# STM32H563_USB_PMA register map
File version: 1.6
STM32G563xx
Registers are 32-bit, read-write, reset 0x0 unless marked. A register's access mark holds for its fields unless they carry their own. Offsets are from the block's base; lines under a group give offsets from that group; [hi:lo] are bit positions; {n}, {i} and the like mark numbered series; 'fields as' and 'values as' point back to an identical list; <NAME> marks a mode.

## Memory map
0x40016400 USB_PMA size 0x400 — USB_PMA2

## USB_PMA — USB_PMA2
Base 0x40016400
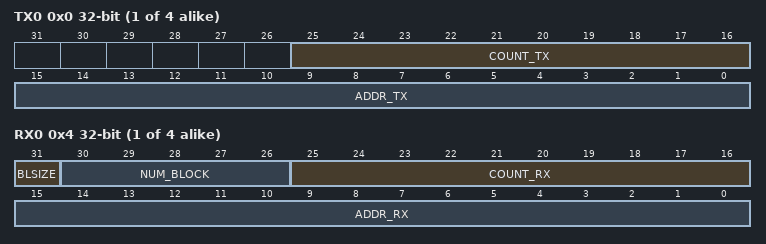
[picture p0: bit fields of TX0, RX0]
{0x0+8i} TX{i} (i=0..3) — See p.2620
  [25:16] COUNT_TX — COUNT0_TX
  [15:0] ADDR_TX — ADDR0_TX
{0x4+8i} RX{i} (i=0..3) — USB PMA transmit
  [31] BLSIZE — 0: 2 byte block size; 1: 32 byte block size
  [30:26] NUM_BLOCK — For 32 byte blocks, 0 = 32 bytes, 1 = 64 bytes; 2 = 96 bytes etc
  [25:16] COUNT_RX
  [15:0] ADDR_RX
0x20 EP0_RX_BUFFER — USB endpoint n register
  [15:0] BUFF0
0x24 EP0_RX_BUFFER2 — USB endpoint n register
  [15:0] BUFF0
0x60 EP0_TX_BUFFER — USB endpoint n register
  [31:0] BUFF0
